# STM32L4x5 register map
File version: 1.8
CPU: CM4 r0p1, little endian, MPU, FPU, 4 interrupt priority bits
Registers are 32-bit, read-write, reset 0x0 unless marked. A register's access mark holds for its fields unless they carry their own. Offsets are from the block's base; [hi:lo] are bit positions; {n}, {i} and the like mark numbered series.

## FIREWALL
Base 0x40011C00
0x00 CSSA — Code segment start address
  [23:8] ADD — code segment start address
0x04 CSL — Code segment length
  [21:8] LENG — code segment length
0x08 NVDSSA — Non-volatile data segment start address
  [23:8] ADD
0x0C NVDSL — Non-volatile data segment length
  [21:8] LENG
0x10 VDSSA — Volatile data segment start address
  [15:6] ADD
0x14 VDSL — Volatile data segment length
  [15:6] LENG — Non-volatile data segment length
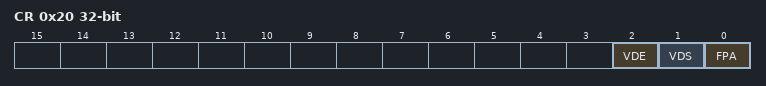
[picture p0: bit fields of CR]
0x20 CR — Configuration register
  [2] VDE — Volatile data execution
    on read: 0=NotExecutable (Volatile data segment cannot be executed if VDS = 0); 1=Executable (Volatile data segment is declared executable whatever VDS bit value) | on write: 0=Resets volatile data execution bit
  [1] VDS — Volatile data shared
    on read: 0=NotShared (Volatile data segment is not shared and cannot be hit by a non protected executable code when the Firewall is closed); 1=Shared (Volatile data segment is shared with non protected application code) | on write: 0=Resets volatile data shared bit
  [0] FPA — Firewall pre alarm
    on write: 0=PreArmReset (Any code executed outside the protected segment when the Firewall is opened will generate a system reset); 1=PreArmSet (Any code executed outside the protected segment will close the Firewall)

## SYSCFG — System configuration controller
Base 0x40010000
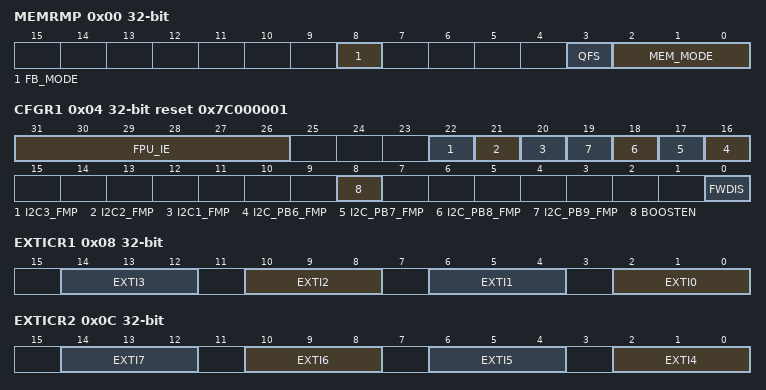
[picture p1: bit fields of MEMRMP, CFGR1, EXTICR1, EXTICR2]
0x00 MEMRMP — memory remap register
  [8] FB_MODE — Flash Bank mode selection
  [3] QFS — QUADSPI memory mapping swap
  [2:0] MEM_MODE — Memory mapping selection
0x04 CFGR1 reset 0x7C000001 — configuration register 1
  [31:26] FPU_IE — Floating Point Unit interrupts enable bits
  [22] I2C3_FMP — I2C3 Fast-mode Plus driving capability activation
  [21] I2C2_FMP — I2C2 Fast-mode Plus driving capability activation
  [20] I2C1_FMP — I2C1 Fast-mode Plus driving capability activation
  [n+10] I2C_PB{n}_FMP (n=6..9) — Fast-mode Plus (Fm+) driving capability activation on PB{n}
  [8] BOOSTEN — I/O analog switch voltage booster enable
  [0] FWDIS — Firewall disable
0x08 EXTICR1 — external interrupt configuration register 1
  [4n+2:4n] EXTI{n} (n=0..3) — EXTI {n} configuration bits
0x0C EXTICR2 — external interrupt configuration register 2
  [4n-14:4n-16] EXTI{n} (n=4..7) — EXTI {n} configuration bits
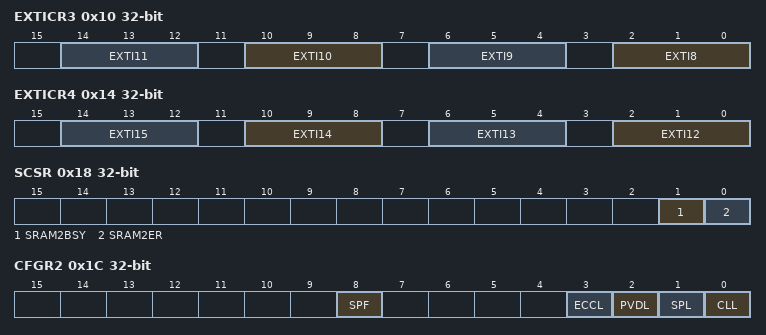
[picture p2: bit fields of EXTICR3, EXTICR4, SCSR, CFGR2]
0x10 EXTICR3 — external interrupt configuration register 3
  [4n-30:4n-32] EXTI{n} (n=8..11) — EXTI {n} configuration bits
0x14 EXTICR4 — external interrupt configuration register 4
  [4n-46:4n-48] EXTI{n} (n=12..15) — EXTI{n} configuration bits
0x18 SCSR access per field
  [1] SRAM2BSY ro — SRAM2 busy by erase operation
  [0] SRAM2ER rw — SRAM2 Erase
0x1C CFGR2 access per field
  [8] SPF rw — SRAM2 parity error flag
  [3] ECCL wo — ECC Lock
  [2] PVDL wo — PVD lock enable bit
  [1] SPL wo — SRAM2 parity lock bit
  [0] CLL wo — Cortex LOCKUP (Hardfault) output enable bit
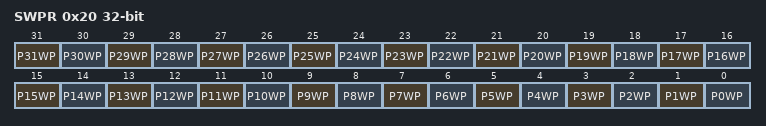
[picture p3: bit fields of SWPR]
0x20 SWPR wo
  [31] P31WP — SRAM2 page 31 write protection
  [n] P{n}WP (n=0..30)
0x24 SKR wo
  [7:0] KEY — SRAM2 write protection key for software erase

## RNG — Random number generator
Base 0x50060800
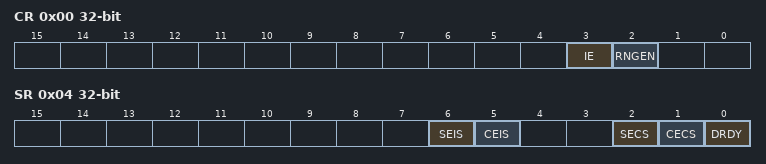
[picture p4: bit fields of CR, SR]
0x00 CR — control register
  [3] IE — Interrupt enable
    0=Disabled (RNG interrupt is disabled); 1=Enabled (RNG interrupt is enabled)
  [2] RNGEN — Random number generator enable
    0=Disabled (Random number generator is disabled); 1=Enabled (Random number generator is enabled)
0x04 SR access per field — status register
  [6] SEIS rw write-0-clears — Seed error interrupt status
    on write: 0=Clear flag | on read: 0=No faulty sequence detected; 1=Fault (At least one faulty sequence has been detected. See **SECS** bit description for details. An interrupt is pending if IE = 1 in the RNG_CR register.)
  [5] CEIS rw write-0-clears — Clock error interrupt status
    on write: 0=Clear flag | on read: 0=Correct (The RNG clock is correct); 1=Slow (The RNG has been detected too slow An interrupt is pending if IE = 1 in the RNG_CR register)
  [2] SECS ro — Seed error current status
    0=No faulty sequence has currently been detected. If the SEIS bit is set, this means that a faulty sequence was detected and the situation has been recovered.; 1=Fault (At least one faulty sequence has been detected - see ref manual for details)
  [1] CECS ro — Clock error current status
    0=Correct (The RNG clock is correct. If the CEIS bit is set, this means that a slow clock was detected and the situation has been recovered.); 1=Slow (The RNG clock is too slow)
  [0] DRDY ro — Data ready
    0=Invalid (The RNG_DR register is not yet valid, no random data is available); 1=Valid (The RNG_DR register contains valid random data. Once the RNG_DR register has been read, this bit returns to 0 until a new random value is generated.)
0x08 DR ro — data register
  [31:0] RNDATA — Random data
